# USB1_VBP2AHB_WRAP_CONTROLLER_VBP_USB3_CORE_SUPPRTCAP2 register map
Vendor: Texas Instruments
Peripheral module from a debugger description file (folder am62P).
Registers are 32-bit, read-only, reset 0x2000002 unless marked. A register's access mark holds for its fields unless they carry their own. Offsets are as the file gives them; lines under a group give offsets from that group; [hi:lo] are bit positions; {n}, {i} and the like mark numbered series; 'fields as' and 'values as' point back to an identical list; <NAME> marks a mode.

## USB1_VBP2AHB_WRAP_CONTROLLER_VBP_USB3_CORE_SUPPRTCAP2
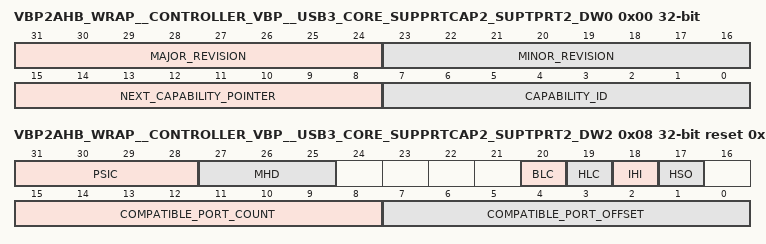
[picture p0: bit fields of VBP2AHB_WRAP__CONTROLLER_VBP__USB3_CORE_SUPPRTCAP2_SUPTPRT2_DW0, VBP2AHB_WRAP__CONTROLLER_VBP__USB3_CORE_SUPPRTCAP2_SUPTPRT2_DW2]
0x00 VBP2AHB_WRAP__CONTROLLER_VBP__USB3_CORE_SUPPRTCAP2_SUPTPRT2_DW0 — SUPTPRT2_DW0
  [31:24] MAJOR_REVISION
  [23:16] MINOR_REVISION
  [15:8] NEXT_CAPABILITY_POINTER
  [7:0] CAPABILITY_ID — CAPABILITY_ID For a description of this standard USB register field, see the eXtensible Host Controller Interface for Universal Serial Bus [USB] Specification 3.0.
0x04 VBP2AHB_WRAP__CONTROLLER_VBP__USB3_CORE_SUPPRTCAP2_SUPTPRT2_DW1 reset 0x20425355 — Register SUPTPRT2_DW1
  [31:0] NAME_STRING — NAME_STRING For a description of this standard USB register field, see the eXtensible Host Controller Interface for Universal Serial Bus [USB] Specification 3.0.
0x08 VBP2AHB_WRAP__CONTROLLER_VBP__USB3_CORE_SUPPRTCAP2_SUPTPRT2_DW2 reset 0x180101 — xHCI Supported Protocol Capability_ Data Word 2 For a description of other register fields, see section 7.2 of the eXtensible Host Controller Interface for Universal Serial Bus (USB) Specification 3.0.
  [31:28] PSIC
  [27:25] MHD — Hub Depth For a description of this standard USB register field, see the eXtensible Host Controller Interface for Universal Serial Bus [USB] Specification 3.0.
  [20] BLC — BESL LPM Capability. When this bit is set to: - 1: The ports described by this xHCI Supported Protocol Capability applies BESL timing to the BESL and BESLD fields of the PORTPMSC and PORTHLPMC registers. - 0: The ports described by this xHCI Supported Protocol Capability applies HIRD timing to the BESL and BESLD fields of the PORTPMSC and PORTHLPMC registers.
  [19] HLC — Compatible Port Offset. Compatible Port Count Refer to Table 7-3 in the Databook.
  [18] IHI
  [17] HSO
  [15:8] COMPATIBLE_PORT_COUNT — COMPATIBLE_PORT_COUNT For a description of this standard USB register field, see the eXtensible Host Controller Interface for Universal Serial Bus [USB] Specification 3.0.
  [7:0] COMPATIBLE_PORT_OFFSET — COMPATIBLE_PORT_OFFSET For a description of this standard USB register field, see the eXtensible Host Controller Interface for Universal Serial Bus [USB] Specification 3.0.
0x0C VBP2AHB_WRAP__CONTROLLER_VBP__USB3_CORE_SUPPRTCAP2_SUPTPRT2_DW3 reset 0x0 — Register SUPTPRT2_DW3
  [4:0] PROTCL_SLT_TY — Protocol Slot Type
